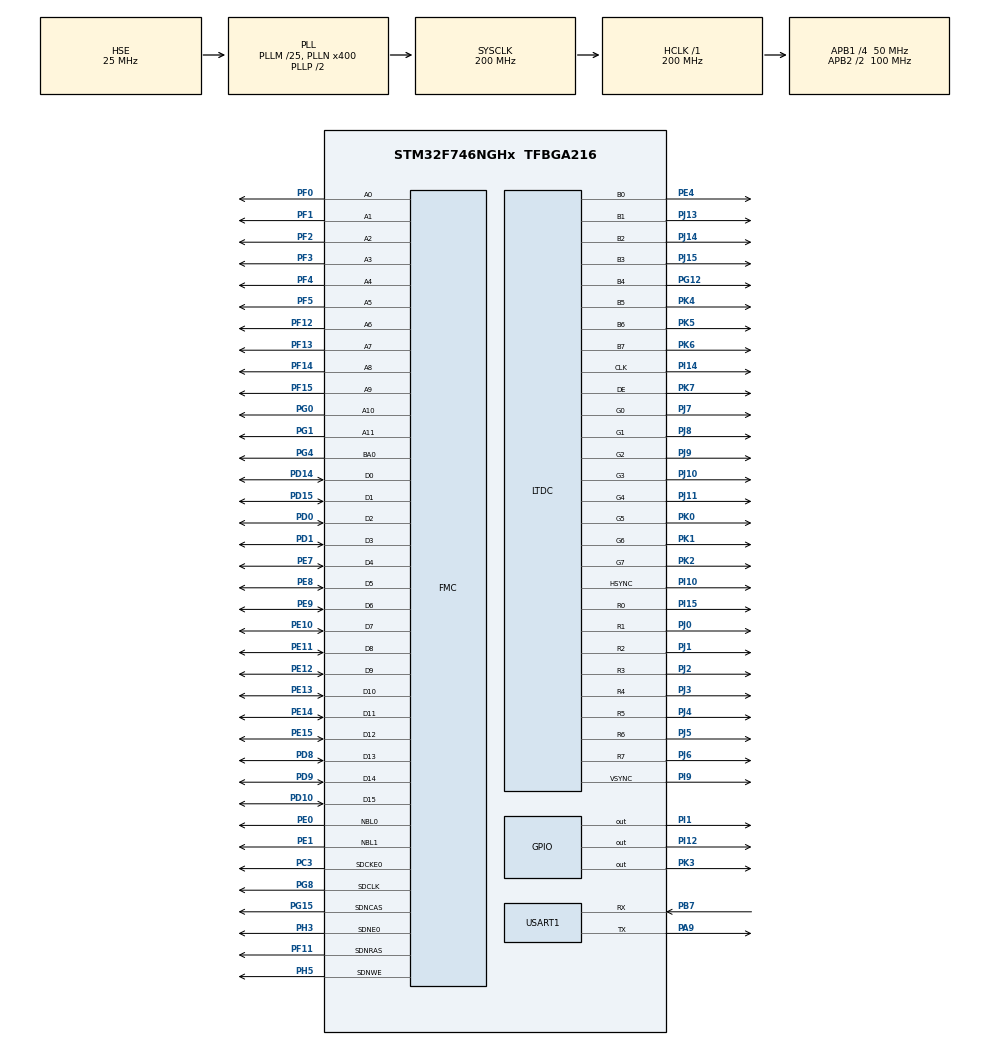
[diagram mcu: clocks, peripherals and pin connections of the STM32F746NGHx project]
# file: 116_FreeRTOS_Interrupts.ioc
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CORTEX_M7.AccessPermission-Cortex_Memory_Protection_Unit_Region0_Settings=MPU_REGION_FULL_ACCESS
CORTEX_M7.BaseAddress-Cortex_Memory_Protection_Unit_Region0_Settings=0xC0000000
CORTEX_M7.CPU_DCache=Enabled
CORTEX_M7.CPU_ICache=Enabled
CORTEX_M7.Enable-Cortex_Memory_Protection_Unit_Region0_Settings=MPU_REGION_ENABLE
CORTEX_M7.IsCacheable-Cortex_Memory_Protection_Unit_Region0_Settings=MPU_ACCESS_CACHEABLE
CORTEX_M7.MPU_Control=MPU_PRIVILEGED_DEFAULT
CORTEX_M7.Size-Cortex_Memory_Protection_Unit_Region0_Settings=MPU_REGION_SIZE_4MB
DMA2D.AlphaModeBackground=DMA2D_REPLACE_ALPHA
DMA2D.AlphaModeForeground=DMA2D_REPLACE_ALPHA
DMA2D.Mode=DMA2D_M2M_BLEND
FMC.CASLatency1=FMC_SDRAM_CAS_LATENCY_2
FMC.ExitSelfRefreshDelay1=6
FMC.LoadToActiveDelay1=2
FMC.RCDDelay1=2
FMC.RPDelay1=2
FMC.RPDelay2=2
FMC.ReadBurst1=FMC_SDRAM_RBURST_ENABLE
FMC.ReadBurst2=FMC_SDRAM_RBURST_ENABLE
FMC.RowCycleDelay1=6
FMC.RowCycleDelay2=6
FMC.SDClockPeriod1=FMC_SDRAM_CLOCK_PERIOD_2
FMC.SDClockPeriod2=FMC_SDRAM_CLOCK_PERIOD_2
FMC.SelfRefreshTime1=4
FMC.WriteRecoveryTime1=2
FREERTOS.Tasks01=defaultTask,0,1280,StartDefaultTask,Default,NULL,Dynamic,NULL,NULL;myTask02,-3,128,StartTask02,Default,NULL,Dynamic,NULL,NULL
FREERTOS.configGENERATE_RUN_TIME_STATS=1
FREERTOS.configTOTAL_HEAP_SIZE=32720
FREERTOS.configUSE_STATS_FORMATTING_FUNCTIONS=1
FREERTOS.configUSE_TRACE_FACILITY=1
LTDC.ActiveH=272
LTDC.ActiveW=480
LTDC.Alpha_L0=255
LTDC.BlendingFactor1_L0=LTDC_BLENDING_FACTOR1_PAxCA
LTDC.BlendingFactor2_L0=LTDC_BLENDING_FACTOR2_PAxCA
LTDC.HBP=13
LTDC.HFP=32
LTDC.HSync=41
LTDC.ImageHeight_L0=272
LTDC.ImageWidth_L0=480
LTDC.Layers=0
LTDC.VSync=10
LTDC.WindowX1_L0=480
LTDC.WindowY1_L0=272
Mcu.Family=STM32F7
Mcu.Name=STM32F746NGHx
Mcu.Package=TFBGA216
NVIC.DMA2D_IRQn=true\:5\:0\:false\:false\:true\:true\:true\:true
NVIC.PriorityGroup=NVIC_PRIORITYGROUP_4
NVIC.TIM1_UP_TIM10_IRQn=true\:0\:0\:false\:false\:true\:false\:false\:true
NVIC.TimeBase=TIM1_UP_TIM10_IRQn
NVIC.TimeBaseIP=TIM1
NVIC.USART1_IRQn=true\:5\:0\:false\:false\:true\:true\:true\:true
PA13.Mode=Serial_Wire
PA13.Signal=SYS_JTMS-SWDIO
PA14.Mode=Serial_Wire
PA14.Signal=SYS_JTCK-SWCLK
PA9.Mode=Asynchronous
PA9.Signal=USART1_TX
PB7.Mode=Asynchronous
PB7.Signal=USART1_RX
PC3.Mode=SdramChipSelect1_1
PC3.Signal=FMC_SDCKE0
PD0.Signal=FMC_D2_DA2
PD1.Signal=FMC_D3_DA3
PD10.Signal=FMC_D15_DA15
PD14.Signal=FMC_D0_DA0
PD15.Signal=FMC_D1_DA1
PD8.Signal=FMC_D13_DA13
PD9.Signal=FMC_D14_DA14
PE0.Signal=FMC_NBL0
PE1.Signal=FMC_NBL1
PE10.Signal=FMC_D7_DA7
PE11.Signal=FMC_D8_DA8
PE12.Signal=FMC_D9_DA9
PE13.Signal=FMC_D10_DA10
PE14.Signal=FMC_D11_DA11
PE15.Signal=FMC_D12_DA12
PE4.GPIO_Speed=GPIO_SPEED_FREQ_HIGH
PE4.Mode=RGB888
PE4.Signal=LTDC_B0
PE7.Signal=FMC_D4_DA4
PE8.Signal=FMC_D5_DA5
PE9.Signal=FMC_D6_DA6
PF0.Signal=FMC_A0
PF1.Signal=FMC_A1
PF11.Signal=FMC_SDNRAS
PF12.Signal=FMC_A6
PF13.Signal=FMC_A7
PF14.Signal=FMC_A8
PF15.Signal=FMC_A9
PF2.Signal=FMC_A2
PF3.Signal=FMC_A3
PF4.Signal=FMC_A4
PF5.Signal=FMC_A5
PG0.Signal=FMC_A10
PG1.Signal=FMC_A11
PG12.GPIO_Speed=GPIO_SPEED_FREQ_HIGH
PG12.Mode=RGB888
PG12.Signal=LTDC_B4
PG15.Signal=FMC_SDNCAS
PG4.Signal=FMC_A14_BA0
PG8.Signal=FMC_SDCLK
PH0/OSC_IN.Mode=HSE-External-Oscillator
PH0/OSC_IN.Signal=RCC_OSC_IN
PH1/OSC_OUT.Mode=HSE-External-Oscillator
PH1/OSC_OUT.Signal=RCC_OSC_OUT
PH3.Mode=SdramChipSelect1_1
PH3.Signal=FMC_SDNE0
PH5.Signal=FMC_SDNWE
PI1.Signal=GPIO_Output
PI10.GPIO_Speed=GPIO_SPEED_FREQ_HIGH
PI10.Mode=RGB888
PI10.Signal=LTDC_HSYNC
PI12.GPIO_Speed=GPIO_SPEED_FREQ_HIGH
PI12.PinState=GPIO_PIN_SET
PI12.Signal=GPIO_Output
PI14.GPIO_Speed=GPIO_SPEED_FREQ_HIGH
PI14.Mode=RGB888
PI14.Signal=LTDC_CLK
PI15.GPIO_Speed=GPIO_SPEED_FREQ_HIGH
PI15.Mode=RGB888
PI15.Signal=LTDC_R0
PI9.GPIO_Speed=GPIO_SPEED_FREQ_HIGH
PI9.Mode=RGB888
PI9.Signal=LTDC_VSYNC
PJ0.GPIO_Speed=GPIO_SPEED_FREQ_HIGH
PJ0.Mode=RGB888
PJ0.Signal=LTDC_R1
PJ1.GPIO_Speed=GPIO_SPEED_FREQ_HIGH
PJ1.Mode=RGB888
PJ1.Signal=LTDC_R2
PJ10.GPIO_Speed=GPIO_SPEED_FREQ_HIGH
PJ10.Mode=RGB888
PJ10.Signal=LTDC_G3
PJ11.GPIO_Speed=GPIO_SPEED_FREQ_HIGH
PJ11.Mode=RGB888
PJ11.Signal=LTDC_G4
PJ13.GPIO_Speed=GPIO_SPEED_FREQ_HIGH
PJ13.Mode=RGB888
PJ13.Signal=LTDC_B1
PJ14.GPIO_Speed=GPIO_SPEED_FREQ_HIGH
PJ14.Mode=RGB888
PJ14.Signal=LTDC_B2
PJ15.GPIO_Speed=GPIO_SPEED_FREQ_HIGH
PJ15.Mode=RGB888
PJ15.Signal=LTDC_B3
PJ2.GPIO_Speed=GPIO_SPEED_FREQ_HIGH
PJ2.Mode=RGB888
PJ2.Signal=LTDC_R3
PJ3.GPIO_Speed=GPIO_SPEED_FREQ_HIGH
PJ3.Mode=RGB888
PJ3.Signal=LTDC_R4
PJ4.GPIO_Speed=GPIO_SPEED_FREQ_HIGH
PJ4.Mode=RGB888
PJ4.Signal=LTDC_R5
PJ5.GPIO_Speed=GPIO_SPEED_FREQ_HIGH
PJ5.Mode=RGB888
PJ5.Signal=LTDC_R6
PJ6.GPIO_Speed=GPIO_SPEED_FREQ_HIGH
PJ6.Mode=RGB888
PJ6.Signal=LTDC_R7
PJ7.GPIO_Speed=GPIO_SPEED_FREQ_HIGH
PJ7.Mode=RGB888
PJ7.Signal=LTDC_G0
PJ8.GPIO_Speed=GPIO_SPEED_FREQ_HIGH
PJ8.Mode=RGB888
PJ8.Signal=LTDC_G1
PJ9.GPIO_Speed=GPIO_SPEED_FREQ_HIGH
PJ9.Mode=RGB888
PJ9.Signal=LTDC_G2
PK0.GPIO_Speed=GPIO_SPEED_FREQ_HIGH
PK0.Mode=RGB888
PK0.Signal=LTDC_G5
PK1.GPIO_Speed=GPIO_SPEED_FREQ_HIGH
PK1.Mode=RGB888
PK1.Signal=LTDC_G6
PK2.GPIO_Speed=GPIO_SPEED_FREQ_HIGH
PK2.Mode=RGB888
PK2.Signal=LTDC_G7
PK3.GPIO_Speed=GPIO_SPEED_FREQ_HIGH
PK3.PinState=GPIO_PIN_SET
PK3.Signal=GPIO_Output
PK4.GPIO_Speed=GPIO_SPEED_FREQ_HIGH
PK4.Mode=RGB888
PK4.Signal=LTDC_B5
PK5.GPIO_Speed=GPIO_SPEED_FREQ_HIGH
PK5.Mode=RGB888
PK5.Signal=LTDC_B6
PK6.GPIO_Speed=GPIO_SPEED_FREQ_HIGH
PK6.Mode=RGB888
PK6.Signal=LTDC_B7
PK7.GPIO_Speed=GPIO_SPEED_FREQ_HIGH
PK7.Mode=RGB888
PK7.Signal=LTDC_DE
ProjectManager.HeapSize=0x2000
ProjectManager.StackSize=0x4000
ProjectManager.TargetToolchain=STM32CubeIDE
RCC.AHBFreq_Value=200000000
RCC.APB1CLKDivider=RCC_HCLK_DIV4
RCC.APB1Freq_Value=50000000
RCC.APB1TimFreq_Value=100000000
RCC.APB2CLKDivider=RCC_HCLK_DIV2
RCC.APB2Freq_Value=100000000
RCC.APB2TimFreq_Value=200000000
RCC.CortexFreq_Value=200000000
RCC.HCLKFreq_Value=200000000
RCC.HSE_VALUE=25000000
RCC.HSI_VALUE=16000000
RCC.LSE_VALUE=32768
RCC.PLLM=25
RCC.PLLN=400
RCC.PLLSAIR=3
RCC.PLLSAIRDiv=RCC_PLLSAIDIVR_4
RCC.PLLSourceVirtual=RCC_PLLSOURCE_HSE
RCC.SYSCLKFreq_VALUE=200000000
RCC.SYSCLKSource=RCC_SYSCLKSOURCE_PLLCLK
RCC.USBFreq_Value=200000000
RCC.VCOOutputFreq_Value=400000000
SH.FMC_A0.0=FMC_A0,12b-sda1
SH.FMC_A1.0=FMC_A1,12b-sda1
SH.FMC_A10.0=FMC_A10,12b-sda1
SH.FMC_A11.0=FMC_A11,12b-sda1
SH.FMC_A14_BA0.0=FMC_BA0,TwoSdramBanks1
SH.FMC_A2.0=FMC_A2,12b-sda1
SH.FMC_A3.0=FMC_A3,12b-sda1
SH.FMC_A4.0=FMC_A4,12b-sda1
SH.FMC_A5.0=FMC_A5,12b-sda1
SH.FMC_A6.0=FMC_A6,12b-sda1
SH.FMC_A7.0=FMC_A7,12b-sda1
SH.FMC_A8.0=FMC_A8,12b-sda1
SH.FMC_A9.0=FMC_A9,12b-sda1
SH.FMC_D0_DA0.0=FMC_D0,sd-16b-d1
SH.FMC_D10_DA10.0=FMC_D10,sd-16b-d1
SH.FMC_D11_DA11.0=FMC_D11,sd-16b-d1
SH.FMC_D12_DA12.0=FMC_D12,sd-16b-d1
SH.FMC_D13_DA13.0=FMC_D13,sd-16b-d1
SH.FMC_D14_DA14.0=FMC_D14,sd-16b-d1
SH.FMC_D15_DA15.0=FMC_D15,sd-16b-d1
SH.FMC_D1_DA1.0=FMC_D1,sd-16b-d1
SH.FMC_D2_DA2.0=FMC_D2,sd-16b-d1
SH.FMC_D3_DA3.0=FMC_D3,sd-16b-d1
SH.FMC_D4_DA4.0=FMC_D4,sd-16b-d1
SH.FMC_D5_DA5.0=FMC_D5,sd-16b-d1
SH.FMC_D6_DA6.0=FMC_D6,sd-16b-d1
SH.FMC_D7_DA7.0=FMC_D7,sd-16b-d1
SH.FMC_D8_DA8.0=FMC_D8,sd-16b-d1
SH.FMC_D9_DA9.0=FMC_D9,sd-16b-d1
SH.FMC_NBL0.0=FMC_NBL0,Sd2ByteEnable1
SH.FMC_NBL1.0=FMC_NBL1,Sd2ByteEnable1
SH.FMC_SDCLK.0=FMC_SDCLK,12b-sda1
SH.FMC_SDNCAS.0=FMC_SDNCAS,12b-sda1
SH.FMC_SDNRAS.0=FMC_SDNRAS,12b-sda1
SH.FMC_SDNWE.0=FMC_SDNWE,12b-sda1
USART1.VirtualMode-Asynchronous=VM_ASYNC
USART1.WordLength=WORDLENGTH_8B
VP_DMA2D_VS_DMA2D.Mode=DMA2D_Activate
VP_FREERTOS_VS_CMSIS_V1.Mode=CMSIS_V1
VP_SYS_VS_tim1.Mode=TIM1
board=CREATE_TASKS

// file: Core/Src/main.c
/* USER CODE BEGIN Header */
/**
  ******************************************************************************
  * @file           : main.c
  * @brief          : Main program body
  ******************************************************************************
  * @attention
  *
  * Copyright (c) 2022 STMicroelectronics.
  * All rights reserved.
  *
  * This software is licensed under terms that can be found in the LICENSE file
  * in the root directory of this software component.
  * If no LICENSE file comes with this software, it is provided AS-IS.
  *
  ******************************************************************************
  */
/* USER CODE END Header */
#include "main.h"
#include "cmsis_os.h"

/* USER CODE BEGIN Includes */

#include "stdint.h"
#include "string.h"
#include "ltdc.h"
#include "MT48LC4M32B2.h"
#include "fonts.h"

/* USER CODE END Includes */

DMA2D_HandleTypeDef hdma2d;

LTDC_HandleTypeDef hltdc;

UART_HandleTypeDef huart1;

SDRAM_HandleTypeDef hsdram1;

osThreadId defaultTaskHandle;
osThreadId myTask02Handle;
/* USER CODE BEGIN PV */

#define LCD_FRAME_BUFFER SDRAM_DEVICE_ADDR
char str1[60];
char buf1[1]; //глобальный буфер для байта, принятого из USART
char str_buf[1000]={'\0'};

osThreadId TaskStringOutHandle, TaskParseUSARTHandle;
osMailQId strout_Queue;
osMessageQId USART_Queue;

typedef struct struct_out_t {
    uint32_t tick_count;
    uint16_t y_pos;
    char str[60];
} struct_out; //Глобальная структура для нашей очереди, в которой будет строка и количество тиков, которое мы также будем передавать из наших задач

#define MAIL_SIZE (uint32_t) 1
#define QUEUE_SIZE (uint32_t) 10 //макрос для размера очереди

/* USER CODE END PV */

void SystemClock_Config(void);
static void MPU_Config(void);
static void MX_GPIO_Init(void);
static void MX_LTDC_Init(void);
static void MX_FMC_Init(void);
static void MX_DMA2D_Init(void);
static void MX_USART1_UART_Init(void);
void StartDefaultTask(void const * argument);
void StartTask02(void const * argument);

/* USER CODE BEGIN PFP */

void TaskParseUSART(void const * argument);
void TaskStringOut(void const * argument);

/* USER CODE END PFP */

int main(void)
{

  /* MPU Configuration--------------------------------------------------------*/
  MPU_Config();

  /* Enable I-Cache---------------------------------------------------------*/
  SCB_EnableICache();

  /* Enable D-Cache---------------------------------------------------------*/
  SCB_EnableDCache();

  /* MCU Configuration--------------------------------------------------------*/

  /* Reset of all peripherals, Initializes the Flash interface and the Systick. */
  HAL_Init();

  /* Configure the system clock */
  SystemClock_Config();

  /* Initialize all configured peripherals */
  MX_GPIO_Init();
  MX_LTDC_Init();
  MX_FMC_Init();
  MX_DMA2D_Init();
  MX_USART1_UART_Init();
  /* USER CODE BEGIN 2 */

  MT48LC4M32B2_init(&hsdram1);
  HAL_LTDC_SetAddress(&hltdc,LCD_FRAME_BUFFER,0);
  TFT_FillScreen(LCD_COLOR_BLACK);
  TFT_SetFont(&Font24);
  TFT_SetTextColor(LCD_COLOR_LIGHTGREEN);
  TFT_DisplayString(0, 10, (uint8_t *)"ISR USART QUEUE", CENTER_MODE);

  /* USER CODE END 2 */

  /* USER CODE BEGIN RTOS_QUEUES */
  /* add queues, ... */

//  osMessageQDef(pos_Queue, QUEUE_SIZE, uint16_t); //Объявили очередь количеством QUEUE_SIZE типа шестнадцатибитного беззнакового целого числа
//  pos_Queue = osMessageCreate(osMessageQ(pos_Queue), NULL);

  osMailQDef(stroutqueue, MAIL_SIZE, struct_out);
  strout_Queue = osMailCreate(osMailQ(stroutqueue), NULL);

  osMessageQDef(usart_Queue, QUEUE_SIZE, uint8_t);
  USART_Queue = osMessageCreate(osMessageQ(usart_Queue), NULL);

  /* USER CODE END RTOS_QUEUES */

  /* Create the thread(s) */
  /* definition and creation of defaultTask */
  osThreadDef(defaultTask, StartDefaultTask, osPriorityNormal, 0, 1280);
  defaultTaskHandle = osThreadCreate(osThread(defaultTask), NULL);

  /* definition and creation of myTask02 */
  osThreadDef(myTask02, StartTask02, osPriorityIdle, 0, 128);
  myTask02Handle = osThreadCreate(osThread(myTask02), NULL);

  /* USER CODE BEGIN RTOS_THREADS */
  /* add threads, ... */

  osThreadDef(tskstrout, TaskStringOut, osPriorityBelowNormal, 0, 1280);
  TaskStringOutHandle = osThreadCreate(osThread(tskstrout), NULL);

  osThreadDef(tskparseusart, TaskParseUSART, osPriorityBelowNormal, 0, 512);
  TaskParseUSARTHandle = osThreadCreate(osThread(tskparseusart), NULL);

  /* USER CODE END RTOS_THREADS */

  /* Start scheduler */
  osKernelStart();

  /* We should never get here as control is now taken by the scheduler */
  /* Infinite loop */
  while (1)
  {

  }
}

void SystemClock_Config(void)
{
  RCC_OscInitTypeDef RCC_OscInitStruct = {0};
  RCC_ClkInitTypeDef RCC_ClkInitStruct = {0};

  /** Configure the main internal regulator output voltage
  */
  __HAL_RCC_PWR_CLK_ENABLE();
  __HAL_PWR_VOLTAGESCALING_CONFIG(PWR_REGULATOR_VOLTAGE_SCALE1);
  /** Initializes the RCC Oscillators according to the specified parameters
  * in the RCC_OscInitTypeDef structure.
  */
  RCC_OscInitStruct.OscillatorType = RCC_OSCILLATORTYPE_HSE;
  RCC_OscInitStruct.HSEState = RCC_HSE_ON;
  RCC_OscInitStruct.PLL.PLLState = RCC_PLL_ON;
  RCC_OscInitStruct.PLL.PLLSource = RCC_PLLSOURCE_HSE;
  RCC_OscInitStruct.PLL.PLLM = 25;
  RCC_OscInitStruct.PLL.PLLN = 400;
  RCC_OscInitStruct.PLL.PLLP = RCC_PLLP_DIV2;
  RCC_OscInitStruct.PLL.PLLQ = 2;
  if (HAL_RCC_OscConfig(&RCC_OscInitStruct) != HAL_OK)
  {
    Error_Handler();
  }
  /** Activate the Over-Drive mode
  */
  if (HAL_PWREx_EnableOverDrive() != HAL_OK)
  {
    Error_Handler();
  }
  /** Initializes the CPU, AHB and APB buses clocks
  */
  RCC_ClkInitStruct.ClockType = RCC_CLOCKTYPE_HCLK|RCC_CLOCKTYPE_SYSCLK
                              |RCC_CLOCKTYPE_PCLK1|RCC_CLOCKTYPE_PCLK2;
  RCC_ClkInitStruct.SYSCLKSource = RCC_SYSCLKSOURCE_PLLCLK;
  RCC_ClkInitStruct.AHBCLKDivider = RCC_SYSCLK_DIV1;
  RCC_ClkInitStruct.APB1CLKDivider = RCC_HCLK_DIV4;
  RCC_ClkInitStruct.APB2CLKDivider = RCC_HCLK_DIV2;

  if (HAL_RCC_ClockConfig(&RCC_ClkInitStruct, FLASH_LATENCY_6) != HAL_OK)
  {
    Error_Handler();
  }
}

static void MX_DMA2D_Init(void)
{

  hdma2d.Instance = DMA2D;
  hdma2d.Init.Mode = DMA2D_M2M_BLEND;
  hdma2d.Init.ColorMode = DMA2D_OUTPUT_ARGB8888;
  hdma2d.Init.OutputOffset = 0;
  hdma2d.LayerCfg[1].InputOffset = 0;
  hdma2d.LayerCfg[1].InputColorMode = DMA2D_INPUT_ARGB8888;
  hdma2d.LayerCfg[1].AlphaMode = DMA2D_REPLACE_ALPHA;
  hdma2d.LayerCfg[1].InputAlpha = 0;
  hdma2d.LayerCfg[0].InputOffset = 0;
  hdma2d.LayerCfg[0].InputColorMode = DMA2D_INPUT_ARGB8888;
  hdma2d.LayerCfg[0].AlphaMode = DMA2D_REPLACE_ALPHA;
  hdma2d.LayerCfg[0].InputAlpha = 0;
//  hdma2d.LayerCfg[0].AlphaInverted = DMA2D_REGULAR_ALPHA;
//  hdma2d.LayerCfg[0].RedBlueSwap = DMA2D_RB_REGULAR;
  if (HAL_DMA2D_Init(&hdma2d) != HAL_OK)
  {
    Error_Handler();
  }
  if (HAL_DMA2D_ConfigLayer(&hdma2d, 0) != HAL_OK)
  {
    Error_Handler();
  }
  if (HAL_DMA2D_ConfigLayer(&hdma2d, 1) != HAL_OK)
  {
    Error_Handler();
  }

}

static void MX_LTDC_Init(void)
{

  LTDC_LayerCfgTypeDef pLayerCfg = {0};

  hltdc.Instance = LTDC;
  hltdc.Init.HSPolarity = LTDC_HSPOLARITY_AL;
  hltdc.Init.VSPolarity = LTDC_VSPOLARITY_AL;
  hltdc.Init.DEPolarity = LTDC_DEPOLARITY_AL;
  hltdc.Init.PCPolarity = LTDC_PCPOLARITY_IPC;
  hltdc.Init.HorizontalSync = 40;
  hltdc.Init.VerticalSync = 9;
  hltdc.Init.AccumulatedHBP = 53;
  hltdc.Init.AccumulatedVBP = 11;
  hltdc.Init.AccumulatedActiveW = 533;
  hltdc.Init.AccumulatedActiveH = 283;
  hltdc.Init.TotalWidth = 565;
  hltdc.Init.TotalHeigh = 285;
  hltdc.Init.Backcolor.Blue = 0;
  hltdc.Init.Backcolor.Green = 0;
  hltdc.Init.Backcolor.Red = 0;
  if (HAL_LTDC_Init(&hltdc) != HAL_OK)
  {
    Error_Handler();
  }
  pLayerCfg.WindowX0 = 0;
  pLayerCfg.WindowX1 = 480;
  pLayerCfg.WindowY0 = 0;
  pLayerCfg.WindowY1 = 272;
  pLayerCfg.PixelFormat = LTDC_PIXEL_FORMAT_ARGB8888;
  pLayerCfg.Alpha = 255;
  pLayerCfg.Alpha0 = 0;
  pLayerCfg.BlendingFactor1 = LTDC_BLENDING_FACTOR1_PAxCA;
  pLayerCfg.BlendingFactor2 = LTDC_BLENDING_FACTOR2_PAxCA;
  pLayerCfg.FBStartAdress = 0;
  pLayerCfg.ImageWidth = 480;
  pLayerCfg.ImageHeight = 272;
  pLayerCfg.Backcolor.Blue = 0;
  pLayerCfg.Backcolor.Green = 0;
  pLayerCfg.Backcolor.Red = 0;
  if (HAL_LTDC_ConfigLayer(&hltdc, &pLayerCfg, 0) != HAL_OK)
  {
    Error_Handler();
  }

}

static void MX_USART1_UART_Init(void)
{

  huart1.Instance = USART1;
  huart1.Init.BaudRate = 115200;
  huart1.Init.WordLength = UART_WORDLENGTH_8B;
  huart1.Init.StopBits = UART_STOPBITS_1;
  huart1.Init.Parity = UART_PARITY_NONE;
  huart1.Init.Mode = UART_MODE_TX_RX;
  huart1.Init.HwFlowCtl = UART_HWCONTROL_NONE;
  huart1.Init.OverSampling = UART_OVERSAMPLING_16;
  huart1.Init.OneBitSampling = UART_ONE_BIT_SAMPLE_DISABLE;
  huart1.AdvancedInit.AdvFeatureInit = UART_ADVFEATURE_NO_INIT;
  if (HAL_UART_Init(&huart1) != HAL_OK)
  {
    Error_Handler();
  }

}

/* FMC initialization function */
static void MX_FMC_Init(void)
{

  FMC_SDRAM_TimingTypeDef SdramTiming = {0};

  /** Perform the SDRAM1 memory initialization sequence
  */
  hsdram1.Instance = FMC_SDRAM_DEVICE;
  /* hsdram1.Init */
  hsdram1.Init.SDBank = FMC_SDRAM_BANK1;
  hsdram1.Init.ColumnBitsNumber = FMC_SDRAM_COLUMN_BITS_NUM_8;
  hsdram1.Init.RowBitsNumber = FMC_SDRAM_ROW_BITS_NUM_12;
  hsdram1.Init.MemoryDataWidth = FMC_SDRAM_MEM_BUS_WIDTH_16;
  hsdram1.Init.InternalBankNumber = FMC_SDRAM_INTERN_BANKS_NUM_2;
  hsdram1.Init.CASLatency = FMC_SDRAM_CAS_LATENCY_2;
  hsdram1.Init.WriteProtection = FMC_SDRAM_WRITE_PROTECTION_DISABLE;
  hsdram1.Init.SDClockPeriod = FMC_SDRAM_CLOCK_PERIOD_2;
  hsdram1.Init.ReadBurst = FMC_SDRAM_RBURST_ENABLE;
  hsdram1.Init.ReadPipeDelay = FMC_SDRAM_RPIPE_DELAY_0;
  /* SdramTiming */
  SdramTiming.LoadToActiveDelay = 2;
  SdramTiming.ExitSelfRefreshDelay = 6;
  SdramTiming.SelfRefreshTime = 4;
  SdramTiming.RowCycleDelay = 6;
  SdramTiming.WriteRecoveryTime = 2;
  SdramTiming.RPDelay = 2;
  SdramTiming.RCDDelay = 2;

  if (HAL_SDRAM_Init(&hsdram1, &SdramTiming) != HAL_OK)
  {
    Error_Handler( );
  }

}

static void MX_GPIO_Init(void)
{
  GPIO_InitTypeDef GPIO_InitStruct = {0};

  /* GPIO Ports Clock Enable */
  __HAL_RCC_GPIOE_CLK_ENABLE();
  __HAL_RCC_GPIOA_CLK_ENABLE();
  __HAL_RCC_GPIOB_CLK_ENABLE();
  __HAL_RCC_GPIOG_CLK_ENABLE();
  __HAL_RCC_GPIOJ_CLK_ENABLE();
  __HAL_RCC_GPIOD_CLK_ENABLE();
  __HAL_RCC_GPIOK_CLK_ENABLE();
  __HAL_RCC_GPIOF_CLK_ENABLE();
  __HAL_RCC_GPIOI_CLK_ENABLE();
  __HAL_RCC_GPIOH_CLK_ENABLE();
  __HAL_RCC_GPIOC_CLK_ENABLE();

  /*Configure GPIO pin Output Level */
  HAL_GPIO_WritePin(GPIOK, GPIO_PIN_3, GPIO_PIN_SET);

  /*Configure GPIO pin Output Level */
  HAL_GPIO_WritePin(GPIOI, GPIO_PIN_1, GPIO_PIN_RESET);

  /*Configure GPIO pin Output Level */
  HAL_GPIO_WritePin(GPIOI, GPIO_PIN_12, GPIO_PIN_SET);

  /*Configure GPIO pin : PK3 */
  GPIO_InitStruct.Pin = GPIO_PIN_3;
  GPIO_InitStruct.Mode = GPIO_MODE_OUTPUT_PP;
  GPIO_InitStruct.Pull = GPIO_NOPULL;
  GPIO_InitStruct.Speed = GPIO_SPEED_FREQ_HIGH;
  HAL_GPIO_Init(GPIOK, &GPIO_InitStruct);

  /*Configure GPIO pin : PI1 */
  GPIO_InitStruct.Pin = GPIO_PIN_1;
  GPIO_InitStruct.Mode = GPIO_MODE_OUTPUT_PP;
  GPIO_InitStruct.Pull = GPIO_NOPULL;
  GPIO_InitStruct.Speed = GPIO_SPEED_FREQ_LOW;
  HAL_GPIO_Init(GPIOI, &GPIO_InitStruct);

  /*Configure GPIO pin : PI12 */
  GPIO_InitStruct.Pin = GPIO_PIN_12;
  GPIO_InitStruct.Mode = GPIO_MODE_OUTPUT_PP;
  GPIO_InitStruct.Pull = GPIO_NOPULL;
  GPIO_InitStruct.Speed = GPIO_SPEED_FREQ_HIGH;
  HAL_GPIO_Init(GPIOI, &GPIO_InitStruct);

}

/* USER CODE BEGIN 4 */

//---------------------------------------------------------------
void TaskStringOut(void const * argument)
{
    osEvent event; //переменная специального типа структуры, предназначенной для свойств и событий очереди
    struct_out *qstruct;   //переменная типа передаваемой в очереди структуры

    for(;;)
    {
        event = osMailGet(strout_Queue, osWaitForever);
        if (event.status == osEventMail)
        {
            qstruct = event.value.p;
            sprintf(str1,"%s %lu", qstruct->str, qstruct->tick_count);
            TFT_DisplayString(120, qstruct->y_pos, (uint8_t *)str1, LEFT_MODE);

        }
    }
}
//---------------------------------------------------------------

//---------------------------------------------------------------
void TaskParseUSART(void const * argument)
{
    osEvent event;
    static char str[30];
    static uint8_t cnt=0;
    uint8_t b;
    int yp;
    struct_out *qstruct;
    TFT_SetTextColor(LCD_COLOR_BLUE);
    for(;;)
    {
        event = osMessageGet(USART_Queue, 100);
        if (event.status == osEventMessage)
        {
            b = event.value.v; //заберём байт из очереди в переменную
            if(cnt>25) //Если превысили количество байтов для строки, обнулим счётчик
            {
              cnt=0;
            }
            str[cnt] = b; //Сохраним байт в массив в позицию, соответствующую значению счётчика
            if(b==0x0A) //Наша тестовая строка будет состоять из двух символов и заканчиваться будет символами возврата каретки и перевода строки. Последний из них будет 0x0A.
            {
                str[cnt-1]=0; //Обнулим предыдущий символ, так как это скорей всего 0x0D. Это и будет окончание принятой строки
                qstruct = osMailAlloc(strout_Queue, osWaitForever); //Выделим память под структуру для очереди и проинициализируем нашу структуру
                qstruct->tick_count = osKernelSysTick();
                yp = atoi(str+7);//Мы преобразовали элемент по 7-му адресу в строке в число. Умножили данное число на 60. Это и будет позиция по вертикали.
                qstruct->y_pos = yp*60;
                //На всякий случай проверим, что мы не ушли за пределы позиции, затем обнулим в строковом массиве элемент,
                //где был индекс позиции, теперь это будет конец строки, так как нам не нужно отображать данное число,
                //затем соответствующему элементу очереди приравняем указатель на нашу строку и отправим нашу структуру в
                //очередь для последующего приёма её в функции задачи, отвечающей за вывод строк на дисплее. Также затем,
                //выйдя из условия, обнулим счётчик
                if ((yp<=3)&&(yp>=1))
                {
                    str[cnt-2]=0;
                    sprintf(qstruct->str, "%s", str);
                    osMailPut(strout_Queue, qstruct);
                }

                cnt=0;
            }
            else cnt++;
        }
    }
}
//---------------------------------------------------------------

//---------------------------------------------------------------
void HAL_UART_RxCpltCallback(UART_HandleTypeDef *huart)
{
    if(huart==&huart1)
    {
        osMessagePut(USART_Queue, buf1[0], 100);
        HAL_UART_Receive_IT(&huart1, (uint8_t*)buf1,1);
    }
}
//---------------------------------------------------------------

/* USER CODE END 4 */

void StartDefaultTask(void const * argument)
{
  /* USER CODE BEGIN 5 */
    osThreadList((unsigned char *)str_buf);
    HAL_UART_Transmit(&huart1, (uint8_t*)str_buf, strlen(str_buf), 0x1000);
    HAL_UART_Transmit(&huart1, (uint8_t*)"\r\n", 2, 0x1000);
    HAL_UART_Receive_IT(&huart1, (uint8_t*)buf1, 1);  //приём данных из USART

  /* Infinite loop */
  for(;;)
  {
      osDelay(1);
  }
  /* USER CODE END 5 */
}

void StartTask02(void const * argument)
{
  for(;;)
  {
      osDelay(1);
  }
}

/* MPU Configuration */

void MPU_Config(void)
{
  MPU_Region_InitTypeDef MPU_InitStruct = {0};

  /* Disables the MPU */
  HAL_MPU_Disable();
  /** Initializes and configures the Region and the memory to be protected
  */
  MPU_InitStruct.Enable = MPU_REGION_ENABLE;
  MPU_InitStruct.Number = MPU_REGION_NUMBER0;
  MPU_InitStruct.BaseAddress = 0xC0000000;
  MPU_InitStruct.Size = MPU_REGION_SIZE_4MB;
  MPU_InitStruct.SubRegionDisable = 0x0;
  MPU_InitStruct.TypeExtField = MPU_TEX_LEVEL0;
  MPU_InitStruct.AccessPermission = MPU_REGION_FULL_ACCESS;
  MPU_InitStruct.DisableExec = MPU_INSTRUCTION_ACCESS_ENABLE;
  MPU_InitStruct.IsShareable = MPU_ACCESS_NOT_SHAREABLE;
  MPU_InitStruct.IsCacheable = MPU_ACCESS_CACHEABLE;
  MPU_InitStruct.IsBufferable = MPU_ACCESS_NOT_BUFFERABLE;

  HAL_MPU_ConfigRegion(&MPU_InitStruct);
  /* Enables the MPU */
  HAL_MPU_Enable(MPU_PRIVILEGED_DEFAULT);

}

void HAL_TIM_PeriodElapsedCallback(TIM_HandleTypeDef *htim)
{
  if (htim->Instance == TIM1) {
    HAL_IncTick();
  }
}

void Error_Handler(void)
{
  __disable_irq();
  while (1)
  {
  }
}
